# STM32WB07 register map
File version: 1.0
Registers are 32-bit, read-write, reset 0x0 unless marked. A register's access mark holds for its fields unless they carry their own. Offsets are from the block's base; [hi:lo] are bit positions; {n}, {i} and the like mark numbered series.

## GPIOA
Base 0x48000000
Same registers: GPIOB 0x48100000
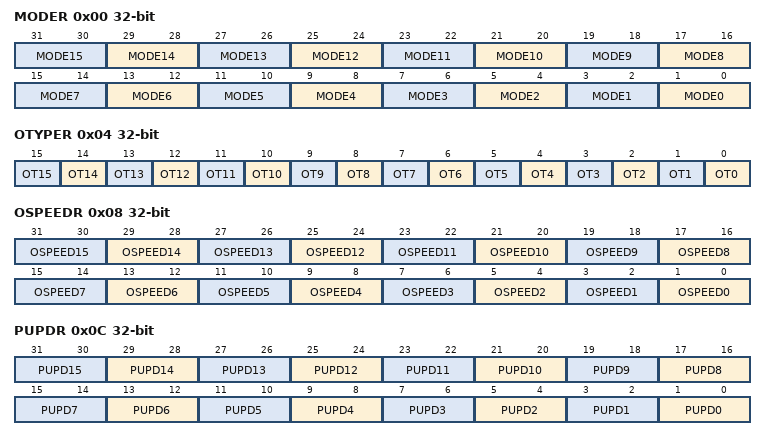
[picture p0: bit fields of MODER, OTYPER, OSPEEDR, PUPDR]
0x00 MODER
  [2n+1:2n] MODE{n} (n=0..15)
0x04 OTYPER
  [n] OT{n} (n=0..15)
0x08 OSPEEDR
  [2n+1:2n] OSPEED{n} (n=0..15)
0x0C PUPDR
  [2n+1:2n] PUPD{n} (n=0..15)
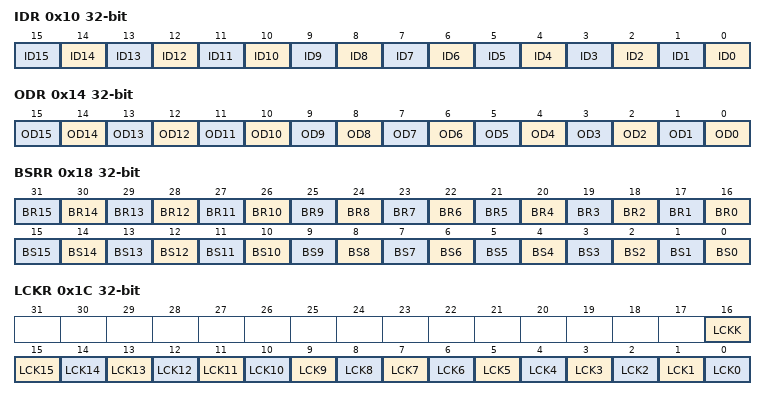
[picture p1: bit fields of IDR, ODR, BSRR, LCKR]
0x10 IDR
  [n] ID{n} (n=0..15)
0x14 ODR
  [n] OD{n} (n=0..15)
0x18 BSRR
  [n+16] BR{n} (n=0..15), [n] BS{n} (n=0..15)
0x1C LCKR
  [16] LCKK, [n] LCK{n} (n=0..15)
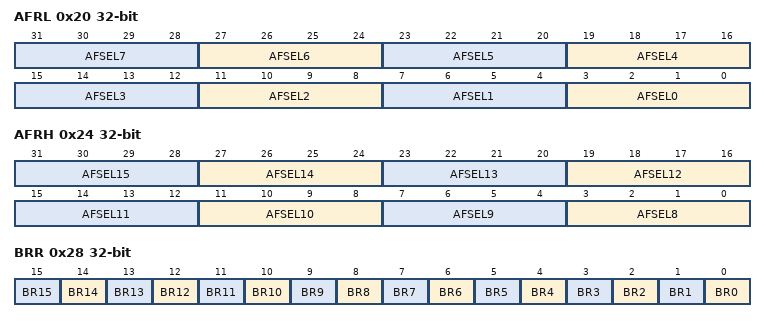
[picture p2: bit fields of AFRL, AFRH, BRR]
0x20 AFRL
  [4n+3:4n] AFSEL{n} (n=0..7)
0x24 AFRH
  [4n-29:4n-32] AFSEL{n} (n=8..15)
0x28 BRR
  [n] BR{n} (n=0..15)

## CRC
Base 0x48200000
0x00 DR
0x04 IDR
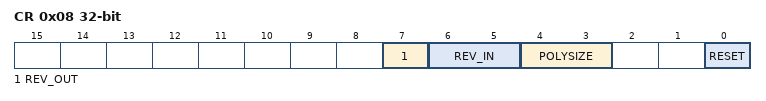
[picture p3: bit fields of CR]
0x08 CR
  [7] REV_OUT
    0=NONE (Output Data bit order not affected); 1=BIT (Output Data bit reversal done by bit)
  [6:5] REV_IN
    0=NONE (Input Data bit order not affected); 1=BYTE (Input Data bit reversal done by byte); 2=HALFWORD (Input Data bit reversal done by half-word); 3=WORD (Input Data bit reversal done by word)
  [4:3] POLYSIZE
    0=POLYLENGTH_32B (32 bits Polynomial size); 1=POLYLENGTH_16B (16 bits Polynomial size); 2=POLYLENGTH_8B (8 bits Polynomial size); 3=POLYLENGTH_7B (7 bits Polynomial size)
  [0] RESET
0x10 INIT
  [31:0] CRC_INIT
0x14 POL

## PKA
Base 0x48300000
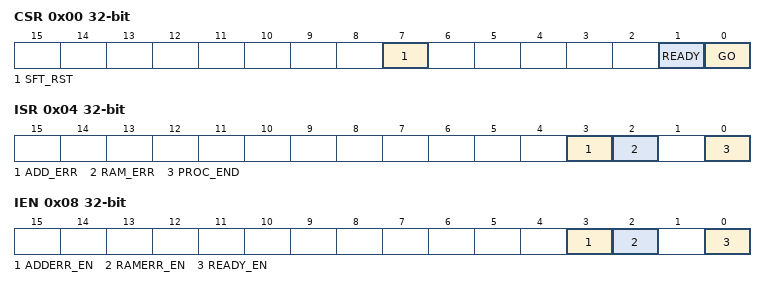
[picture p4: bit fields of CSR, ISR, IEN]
0x00 CSR
  [7] SFT_RST, [1] READY, [0] GO
0x04 ISR
  [3] ADD_ERR, [2] RAM_ERR, [0] PROC_END
0x08 IEN
  [3] ADDERR_EN, [2] RAMERR_EN, [0] READY_EN
{0x400+4i} RAM[{i}] (i=0..255)

## PWR
Base 0x48500000
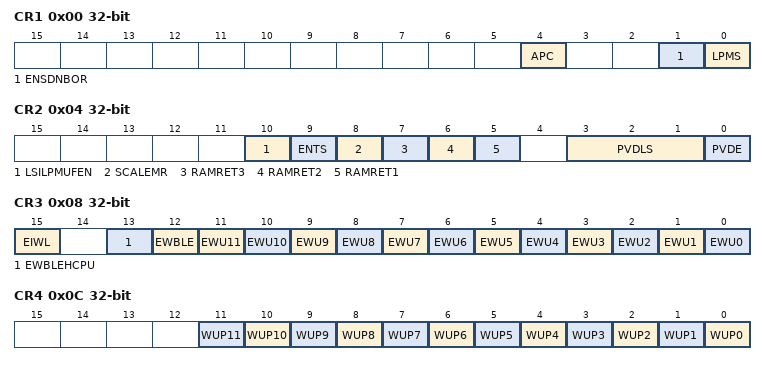
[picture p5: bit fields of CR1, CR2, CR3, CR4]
0x00 CR1
  [4] APC
  [1] ENSDNBOR
  [0] LPMS
    0=DEEPSTOP; 1=SHUTDOWN
0x04 CR2
  [10] LSILPMUFEN
  [9] ENTS
  [8] SCALEMR
  [7] RAMRET3
  [6] RAMRET2
  [5] RAMRET1
  [3:1] PVDLS
    0=PVDLEVEL_0 (VPVD0 around 2.0 V); 1=PVDLEVEL_1 (VPVD1 around 2.2 V); 2=PVDLEVEL_2 (VPVD2 around 2.4 V); 3=PVDLEVEL_3 (VPVD3 around 2.5 V); 4=PVDLEVEL_4 (VPVD4 around 2.6 V); 5=PVDLEVEL_5 (VPVD5 around 2.8 V); 6=PVDLEVEL_6 (VPVD6 around 2.9 V); 7=PVDLEVEL_7 (External input analog voltage (Compare internally to VBGP))
  [0] PVDE
0x08 CR3
  [15] EIWL, [13] EWBLEHCPU, [12] EWBLE, [n] EWU{n} (n=0..11)
0x0C CR4
  [n] WUP{n} (n=0..11)
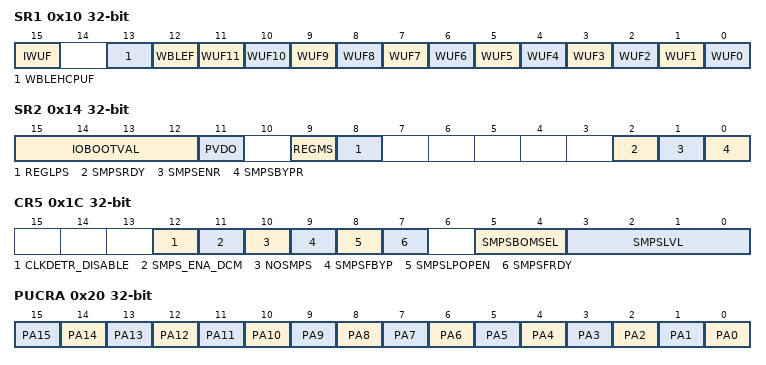
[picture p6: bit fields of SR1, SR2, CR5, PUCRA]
0x10 SR1
  [15] IWUF, [13] WBLEHCPUF, [12] WBLEF, [n] WUF{n} (n=0..11)
0x14 SR2
  [15:12] IOBOOTVAL, [11] PVDO, [9] REGMS, [8] REGLPS, [2] SMPSRDY, [1] SMPSENR, [0] SMPSBYPR
0x1C CR5
  [12] CLKDETR_DISABLE
  [11] SMPS_ENA_DCM
  [10] NOSMPS
    0=SMPS (SMPS is enabled); 1=NO_SMPS (SMPS is disabled)
  [9] SMPSFBYP
    0=NO_SMPS_PRECHARGE (SMPS not in pecharge mode); 1=SMPS_PRECHARGE (SMPS is disabled and bypassed in precharge mode)
  [8] SMPSLPOPEN
    0=NO_SMPS_LPOPEN (In DEEPSTOP, the SMPS is in PRECHARGE mode with output connected to VDDIO); 1=SMPS_LPOPEN (In DEEPSTOP, the SMPS is disabled with floating output)
  [7] SMPSFRDY
  [5:4] SMPSBOMSEL
    0=BOM1; 1=BOM2; 2=BOM3
  [3:0] SMPSLVL
    0=VOLTAGE_1V20 (SMPS step down converter supply output voltage 1.20V); 1=VOLTAGE_1V25 (SMPS step down converter supply output voltage 1.25V); 2=VOLTAGE_1V30 (SMPS step down converter supply output voltage 1.30V); 3=VOLTAGE_1V35 (SMPS step down converter supply output voltage 1.35V); 4=VOLTAGE_1V40 (SMPS step down converter supply output voltage 1.40V); 5=VOLTAGE_1V45 (SMPS step down converter supply output voltage 1.45V); 6=VOLTAGE_1V50 (SMPS step down converter supply output voltage 1.50V); 7=VOLTAGE_1V55 (SMPS step down converter supply output voltage 1.55V); 8=VOLTAGE_1V60 (SMPS step down converter supply output voltage 1.60V); 9=VOLTAGE_1V65 (SMPS step down converter supply output voltage 1.65V); 10=VOLTAGE_1V70 (SMPS step down converter supply output voltage 1.70V); 11=VOLTAGE_1V75 (SMPS step down converter supply output voltage 1.75V); 12=VOLTAGE_1V80 (SMPS step down converter supply output voltage 1.80V); 13=VOLTAGE_1V85 (SMPS step down converter supply output voltage 1.85V); 14=VOLTAGE_1V90 (SMPS step down converter supply output voltage 1.90V); 15=VOLTAGE_1V95 (SMPS step down converter supply output voltage 1.95V)
0x20 PUCRA
  [n] PA{n} (n=0..15)
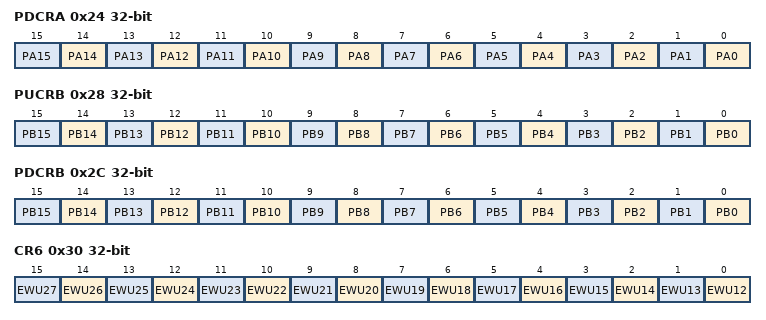
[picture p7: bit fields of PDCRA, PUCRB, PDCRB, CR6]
0x24 PDCRA
  [n] PA{n} (n=0..15)
0x28 PUCRB
  [n] PB{n} (n=0..15)
0x2C PDCRB
  [n] PB{n} (n=0..15)
0x30 CR6
  [n-12] EWU{n} (n=12..27)
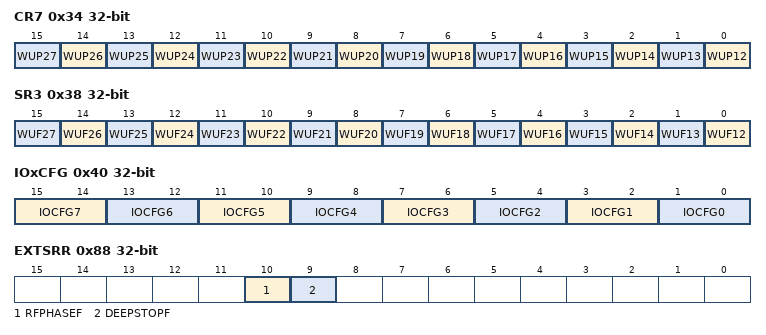
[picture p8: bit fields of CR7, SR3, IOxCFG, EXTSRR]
0x34 CR7
  [n-12] WUP{n} (n=12..27)
0x38 SR3
  [n-12] WUF{n} (n=12..27)
0x40 IOxCFG
  [2n+1:2n] IOCFG{n} (n=1..7)
  [1:0] IOCFG0
    0=BYP; 1=LCO (LCO output signal for PA10 and PA9); 2=LOW (I/O drives a low level in both active and DEEPSTOP modes); 3=HIGH (I/O drives a high level in both active and DEEPSTOP modes)
0x84 DBGR
  [0] DEEPSTOP2
0x88 EXTSRR
  [10] RFPHASEF, [9] DEEPSTOPF
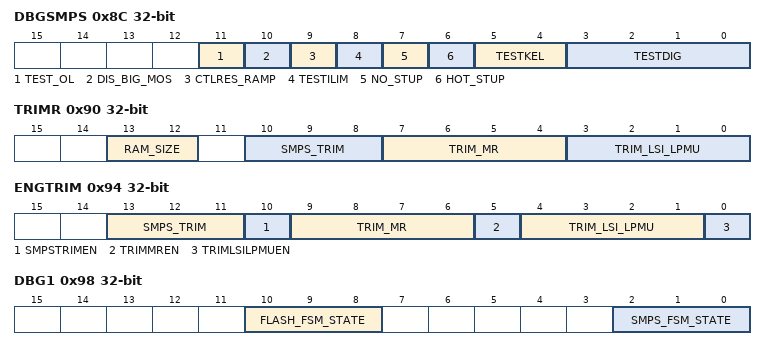
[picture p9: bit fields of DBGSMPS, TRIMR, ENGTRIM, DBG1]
0x8C DBGSMPS
  [11] TEST_OL, [10] DIS_BIG_MOS, [9] CTLRES_RAMP, [8] TESTILIM, [7] NO_STUP, [6] HOT_STUP, [5:4] TESTKEL, [3:0] TESTDIG
0x90 TRIMR
  [13:12] RAM_SIZE, [10:8] SMPS_TRIM, [7:4] TRIM_MR, [3:0] TRIM_LSI_LPMU
0x94 ENGTRIM
  [13:11] SMPS_TRIM, [10] SMPSTRIMEN, [9:6] TRIM_MR, [5] TRIMMREN, [4:1] TRIM_LSI_LPMU, [0] TRIMLSILPMUEN
0x98 DBG1
  [10:8] FLASH_FSM_STATE, [2:0] SMPS_FSM_STATE
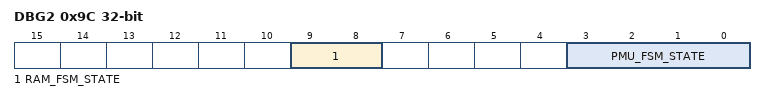
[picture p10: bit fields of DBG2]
0x9C DBG2
  [9:8] RAM_FSM_STATE, [3:0] PMU_FSM_STATE
